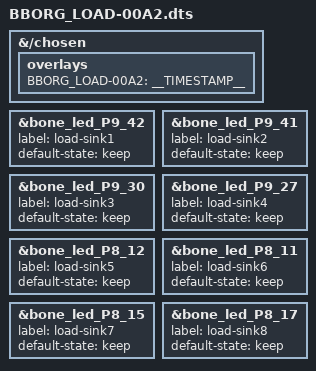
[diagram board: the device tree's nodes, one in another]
// SPDX-License-Identifier: GPL-2.0-only
/*
 * Copyright (C) 2020 - 2022 Deepak Khatri <lorforlinux@beagleboard.org>
 * See Cape Interface Spec page for more info on Bone Buses
 * https://docs.beagleboard.org/0.0/boards/capes/cape-interface-spec.html#beaglebone-cape-interface-spec
 *
 */

/dts-v1/;
/plugin/;

/*
 * Helper to show loaded overlays under: /proc/device-tree/chosen/overlays/
 */
&{/chosen} {
	overlays {
		BBORG_LOAD-00A2 = __TIMESTAMP__;
	};
};

/*
 * Easy load control through sysfs (/sys/class/leds/) using gpio-leds driver 
 */

&bone_led_P9_42 {
    status = "okay";
    label = "load-sink1";
    default-state = "keep";
};

&bone_led_P9_41 {
    status = "okay";
    label = "load-sink2";
    default-state = "keep";
};

&bone_led_P9_30 {
    status = "okay";
    label = "load-sink3";
    default-state = "keep";
};

&bone_led_P9_27 {
    status = "okay";
    label = "load-sink4";
    default-state = "keep";
};

&bone_led_P8_12 {
    status = "okay";
    label = "load-sink5";
    default-state = "keep";
};

&bone_led_P8_11 {
    status = "okay";
    label = "load-sink6";
    default-state = "keep";
};

&bone_led_P8_15 {
    status = "okay";
    label = "load-sink7";
    default-state = "keep";
};

&bone_led_P8_17 {
    status = "okay";
    label = "load-sink8";
    default-state = "keep";
};
